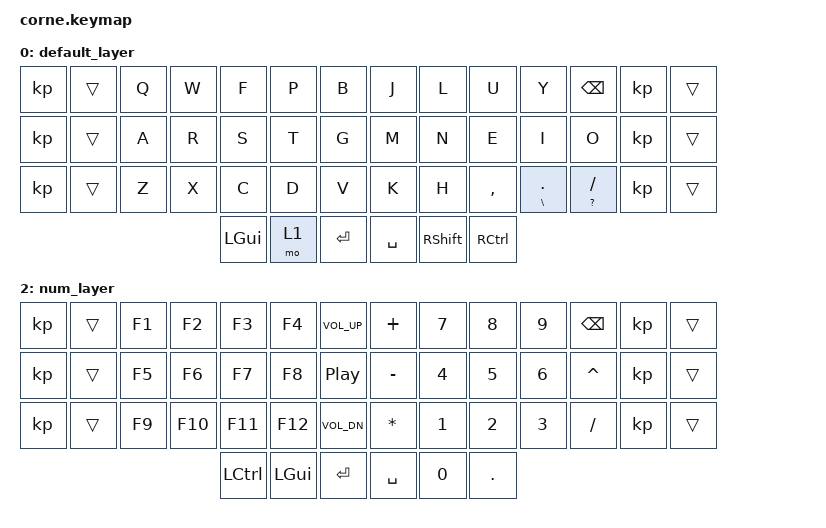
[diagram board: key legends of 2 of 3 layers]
#include <behaviors.dtsi>
#include <dt-bindings/zmk/keys.h>
#include <dt-bindings/zmk/bt.h>

#define XXX &none
#define ___ &trans
#define iHOMsel RG(RS(LEFT))
#define iENDsel RG(RS(RIGHT))
#define selAll RG(A)
#define ctRight LC(TAB)
#define ctLeft LC(RS(TAB))
#define rGra RG(GRAVE)
#define rsGra RG(RS(GRAVE))
#define reDo RG(RS(Z))
#define unDo RG(Z)

&mt {
    tapping-term-ms = <300>;
};

/ {
    behaviors {
        hm: hold_mods {
            compatible = "zmk,behavior-hold-tap";
            label = "HOLD_TAP";
            #binding-cells = <2>;
            tapping-term-ms = <180>;
            quick_tap_ms = <0>;
            flavor = "balanced";
            bindings = <&kp>, <&kp>;
        };
        skq: sticky_key_quick_release {
            compatible = "zmk,behavior-sticky-key";
            label = "STICKY_KEY_QUICK_RELEASE";
            #binding-cells = <1>;
            bindings = <&kp>;
            release-after-ms = <2000>;
            quick-release;
        };
        lst: layer_sticky_tap {
            compatible = "zmk,behavior-hold-tap";
            label = "LAYER_STICKY_TAP";
            #binding-cells = <2>;
            tapping-term-ms = <200>;
            quick_tap_ms = <0>;
            flavor = "tap-preferred";
            bindings = <&mo>, <&sk>;
        };
    };

    combos {
        #include "combos.dtsi"
    };

    keymap {
      compatible = "zmk,keymap";

    	default_layer {
    		bindings = <
            // ╭─────────────┬─────────────┬─────────────┬─────────────┬─────────────╮   ╭─────────────┬─────────────┬─────────────┬─────────────┬─────────────╮
       &kp ___   &kp Q         &kp W         &kp F         &kp P         &kp B             &kp J         &kp L         &kp U         &kp Y         &kp BSPC  &kp ___   
            // ├─────────────┼─────────────┼─────────────┼─────────────┼─────────────┤   ├─────────────┼─────────────┼─────────────┼─────────────┼─────────────┤
       &kp ___   &kp A         &kp R         &kp S         &kp T         &kp G             &kp M         &kp N         &kp E         &kp I         &kp O     &kp ___   
            // ├─────────────┼─────────────┼─────────────┼─────────────┼─────────────┤   ├─────────────┼─────────────┼─────────────┼─────────────┼─────────────┤
       &kp ___   &kp Z         &kp X         &kp C         &kp D         &kp V	           &kp K         &kp H         &kp COMMA     &hm BSLH DOT  &hm QMARK SLASH    &kp ___   
            // ╰─────────────┴─────────────┼─────────────┼─────────────┼─────────────┤   ├─────────────┼─────────────┼─────────────┼─────────────┴─────────────╯
                                             &kp LGUI      &mo  1        &kp RET           &kp SPACE     &kp RSHFT     &kp RCTRL
            //                             ╰─────────────┴─────────────┴─────────────╯   ╰─────────────┴─────────────┴─────────────╯
		    >;
      };

      nav_layer {
          bindings = <
          // ╭─────────────┬─────────────┬─────────────┬─────────────┬─────────────╮   ╭─────────────┬─────────────┬─────────────┬─────────────┬─────────────╮
 &kp ___                  &kp N1       &kp N2        &kp N3        &kp N4        &kp N5            &kp N6        &kp N7        &kp N8        &kp N9        &kp N0   &kp ___   
          // ├─────────────┼─────────────┼─────────────┼─────────────┼─────────────┤   ├─────────────┼─────────────┼─────────────┼─────────────┼─────────────┤
 &kp ___                 &kp rGra      &kp rsGra     &kp ctLeft    &kp ctRight   &kp RG(C)         &kp selAll    &kp LEFT      &kp DOWN      &kp UP        &kp RIGHT   &kp ___   
          // ├─────────────┼─────────────┼─────────────┼─────────────┼─────────────┤   ├─────────────┼─────────────┼─────────────┼─────────────┼─────────────┤
 &kp ___                 &kp unDo      &kp reDo      &kp XXX       &kp RG(X)     &kp RG(V)         &kp iHOMsel   &kp iHOMsel   &kp PG_DN     &kp PG_UP     &kp iENDsel  &kp ___   
          // ╰─────────────┴─────────────┼─────────────┼─────────────┼─────────────┤   ├─────────────┼─────────────┼─────────────┼─────────────┴─────────────╯
                                           &kp ___       &kp XXX       &skq LALT         &kp RG(LEFT)  &kp RSHFT     &kp RG(RIGHT)
          //                             ╰─────────────┴─────────────┴─────────────╯   ╰─────────────┴─────────────┴─────────────╯
          >;
      };

      num_layer {
          bindings = <
          // ╭─────────────┬─────────────┬─────────────┬─────────────┬─────────────╮   ╭─────────────┬─────────────┬─────────────┬─────────────┬─────────────╮
 &kp ___                 &kp F1        &kp F2        &kp F3        &kp F4        &kp C_VOL_UP      &kp PLUS      &kp N7        &kp N8        &kp N9        &kp BSPC   &kp ___   
          // ├─────────────┼─────────────┼─────────────┼─────────────┼─────────────┤   ├─────────────┼─────────────┼─────────────┼─────────────┼─────────────┤
 &kp ___                 &kp F5        &kp F6        &kp F7        &kp F8        &kp C_PP          &kp MINUS     &kp N4        &kp N5        &kp N6        &kp CARET   &kp ___   
          // ├─────────────┼─────────────┼─────────────┼─────────────┼─────────────┤   ├─────────────┼─────────────┼─────────────┼─────────────┼─────────────┤
 &kp ___                 &kp F9        &kp F10       &kp F11       &kp F12       &kp C_VOL_DN      &kp STAR      &kp N1        &kp N2        &kp N3        &kp SLASH   &kp ___   
          // ╰─────────────┴─────────────┼─────────────┼─────────────┼─────────────┤   ├─────────────┼─────────────┼─────────────┼─────────────┴─────────────╯
                                           &kp LCTRL     &kp LGUI      &kp RET           &kp SPACE     &kp N0        &kp DOT
          //                             ╰─────────────┴─────────────┴─────────────╯   ╰─────────────┴─────────────┴─────────────╯
          >;
      };
    };
};
